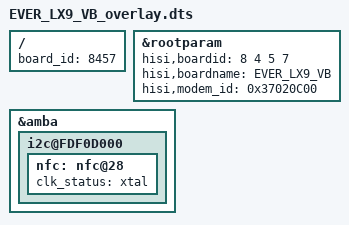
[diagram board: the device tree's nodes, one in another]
/**
 * Copyright (C) 2014 Hisilicon Ltd.
 *
 *  This program is free software; you can redistribute it and/or modify
 *  it under the terms of the GNU General Public License version 2 as
 *  publishhed by the Free Software Foundation.
 */

/dts-v1/;
/plugin/;

/include/ "EVER_LX9_VA_overlay.dtsi"
/include/ "EVER_LX9_VB_pin.dtsi"
/include/ "EVER_LX9_VB_modem_pin.dtsi"

/ {
    board_id = <8457>;
};
	&rootparam{
		hisi,boardid = <8 4 5 7>;
		hisi,boardname = "EVER_LX9_VB";
		hisi,modem_id = <0x37020C00>;
	};
        &amba {
            i2c@FDF0D000 {
                    nfc:nfc@28{
                            clk_status = "xtal";
                    };
            };
        };
